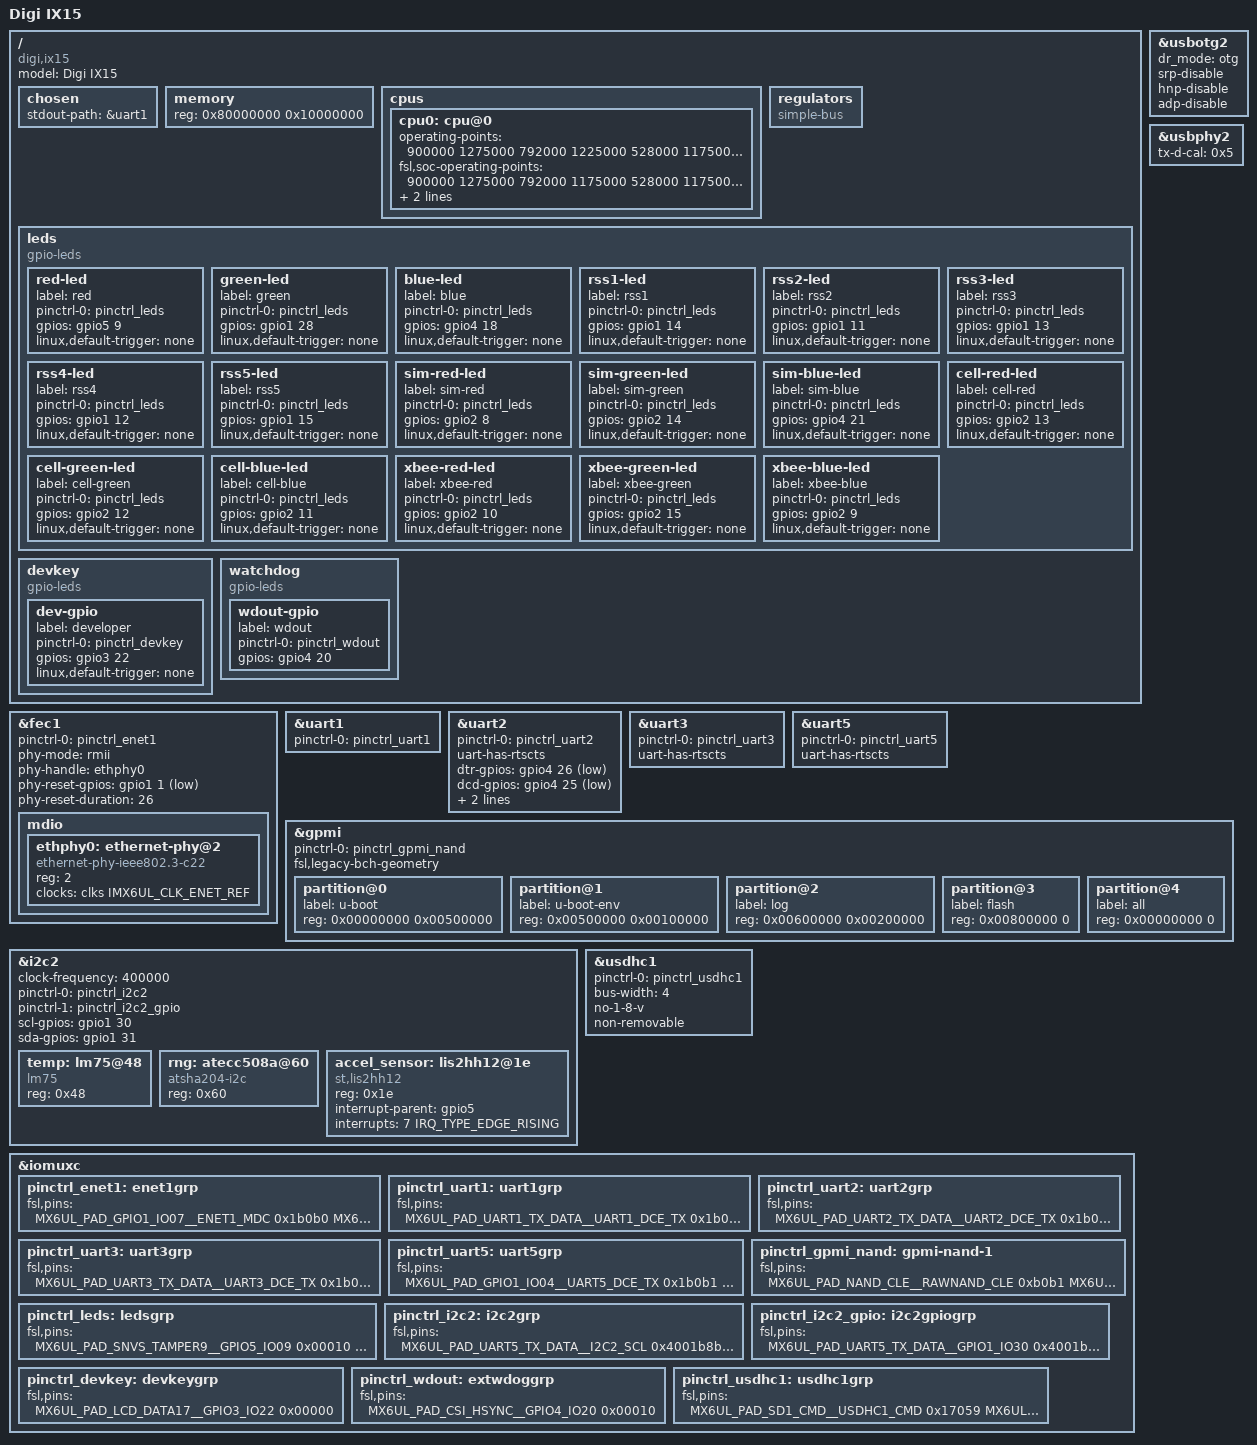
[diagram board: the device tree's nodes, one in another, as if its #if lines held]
/*
 * Copyright (C) 2016 Freescale Semiconductor, Inc.
 * Copyright (C) 2020 Digi International
 *
 * This program is free software; you can redistribute it and/or modify
 * it under the terms of the GNU General Public License version 2 as
 * published by the Free Software Foundation.
 */

/dts-v1/;

#include "imx6ull.dtsi"

/ {
	model = "Digi IX15";
	compatible = "digi,ix15", "fsl,imx6ull";

	chosen {
		stdout-path = &uart1;
	};

	memory {
		device_type = "memory";
		reg = <0x80000000 0x10000000>;
	};

	cpus {
		cpu0: cpu@0 {
			operating-points = <
                                /* kHz  uV */
                                900000  1275000
				792000	1225000
                                528000  1175000
                                396000  1025000
                                198000  950000
                        >;
                        fsl,soc-operating-points = <
                                /* KHz  uV */
                                900000  1275000
				792000	1175000
                                528000  1175000
                                396000  1175000
                                198000  1175000
                        >;
		};
	};

	regulators {
		compatible = "simple-bus";
		#address-cells = <1>;
		#size-cells = <0>;
	};

	leds {
		compatible = "gpio-leds";

		red-led {
			label = "red";
			pinctrl-names = "default";
			pinctrl-0 = <&pinctrl_leds>;
			gpios = <&gpio5 9 GPIO_ACTIVE_HIGH>;
			linux,default-trigger = "none";
		};

		green-led {
			label = "green";
			pinctrl-names = "default";
			pinctrl-0 = <&pinctrl_leds>;
			gpios = <&gpio1 28 GPIO_ACTIVE_HIGH>;
			linux,default-trigger = "none";
		};

		blue-led {
			label = "blue";
			pinctrl-names = "default";
			pinctrl-0 = <&pinctrl_leds>;
			gpios = <&gpio4 18 GPIO_ACTIVE_HIGH>;
			linux,default-trigger = "none";
		};

		rss1-led {
			label = "rss1";
			pinctrl-names = "default";
			pinctrl-0 = <&pinctrl_leds>;
			gpios = <&gpio1 14 GPIO_ACTIVE_HIGH>;
			linux,default-trigger = "none";
		};

		rss2-led {
			label = "rss2";
			pinctrl-names = "default";
			pinctrl-0 = <&pinctrl_leds>;
			gpios = <&gpio1 11 GPIO_ACTIVE_HIGH>;
			linux,default-trigger = "none";
		};

		rss3-led {
			label = "rss3";
			pinctrl-names = "default";
			pinctrl-0 = <&pinctrl_leds>;
			gpios = <&gpio1 13 GPIO_ACTIVE_HIGH>;
			linux,default-trigger = "none";
		};

		rss4-led {
			label = "rss4";
			pinctrl-names = "default";
			pinctrl-0 = <&pinctrl_leds>;
			gpios = <&gpio1 12 GPIO_ACTIVE_HIGH>;
			linux,default-trigger = "none";
		};

		rss5-led {
			label = "rss5";
			pinctrl-names = "default";
			pinctrl-0 = <&pinctrl_leds>;
			gpios = <&gpio1 15 GPIO_ACTIVE_HIGH>;
			linux,default-trigger = "none";
		};

		sim-red-led {
			label = "sim-red";
			pinctrl-names = "default";
			pinctrl-0 = <&pinctrl_leds>;
			gpios = <&gpio2 8 GPIO_ACTIVE_HIGH>;
			linux,default-trigger = "none";
		};

		sim-green-led {
			label = "sim-green";
			pinctrl-names = "default";
			pinctrl-0 = <&pinctrl_leds>;
			gpios = <&gpio2 14 GPIO_ACTIVE_HIGH>;
			linux,default-trigger = "none";
		};

		sim-blue-led {
			label = "sim-blue";
			pinctrl-names = "default";
			pinctrl-0 = <&pinctrl_leds>;
			gpios = <&gpio4 21 GPIO_ACTIVE_HIGH>;
			linux,default-trigger = "none";
		};

		cell-red-led {
			label = "cell-red";
			pinctrl-names = "default";
			pinctrl-0 = <&pinctrl_leds>;
			gpios = <&gpio2 13 GPIO_ACTIVE_HIGH>;
			linux,default-trigger = "none";
		};

		cell-green-led {
			label = "cell-green";
			pinctrl-names = "default";
			pinctrl-0 = <&pinctrl_leds>;
			gpios = <&gpio2 12 GPIO_ACTIVE_HIGH>;
			linux,default-trigger = "none";
		};

		cell-blue-led {
			label = "cell-blue";
			pinctrl-names = "default";
			pinctrl-0 = <&pinctrl_leds>;
			gpios = <&gpio2 11 GPIO_ACTIVE_HIGH>;
			linux,default-trigger = "none";
		};

		xbee-red-led {
			label = "xbee-red";
			pinctrl-names = "default";
			pinctrl-0 = <&pinctrl_leds>;
			gpios = <&gpio2 10 GPIO_ACTIVE_HIGH>;
			linux,default-trigger = "none";
		};

		xbee-green-led {
			label = "xbee-green";
			pinctrl-names = "default";
			pinctrl-0 = <&pinctrl_leds>;
			gpios = <&gpio2 15 GPIO_ACTIVE_HIGH>;
			linux,default-trigger = "none";
		};

		xbee-blue-led {
			label = "xbee-blue";
			pinctrl-names = "default";
			pinctrl-0 = <&pinctrl_leds>;
			gpios = <&gpio2 9 GPIO_ACTIVE_HIGH>;
			linux,default-trigger = "none";
		};
	};

	devkey {
		compatible = "gpio-leds";

		dev-gpio {
			label = "developer";
			pinctrl-names = "default";
			pinctrl-0 = <&pinctrl_devkey>;
			gpios = <&gpio3 22 GPIO_ACTIVE_HIGH>;
			linux,default-trigger = "none";
		};
	};

	watchdog {
		compatible = "gpio-leds";

		wdout-gpio {
			label = "wdout";
			pinctrl-names = "default";
			pinctrl-0 = <&pinctrl_wdout>;
			gpios = <&gpio4 20 GPIO_ACTIVE_HIGH>;
		};
	};
};

&cpu0 {
	arm-supply = <&reg_arm>;
	soc-supply = <&reg_soc>;
};

&fec1 {
	pinctrl-names = "default";
	pinctrl-0 = <&pinctrl_enet1>;
	phy-mode = "rmii";
	phy-handle = <&ethphy0>;
	phy-reset-gpios = <&gpio1 1 GPIO_ACTIVE_LOW>;
	phy-reset-duration = <26>;
	status = "okay";

	mdio {
		#address-cells = <1>;
		#size-cells = <0>;

		ethphy0: ethernet-phy@2 {
			compatible = "ethernet-phy-ieee802.3-c22";
			reg = <2>;
			clocks = <&clks IMX6UL_CLK_ENET_REF>;
			clock-names = "rmii-ref";
		};
	};
};

/* Console */
&uart1 {
	pinctrl-names = "default";
	pinctrl-0 = <&pinctrl_uart1>;
	status = "okay";
};

/* RS232/RS485 */
&uart2 {
	pinctrl-names = "default";
	pinctrl-0 = <&pinctrl_uart2>;
	uart-has-rtscts;
	dtr-gpios = <&gpio4 26 GPIO_ACTIVE_LOW>;
	dcd-gpios = <&gpio4 25 GPIO_ACTIVE_LOW>;
	dsr-gpios = <&gpio4 27 GPIO_ACTIVE_LOW>;
	rng-gpios = <&gpio3 3 GPIO_ACTIVE_LOW>;
	status = "okay";
};

#ifdef IX15_BLE
/* BLE */
&uart3 {
	pinctrl-names = "default";
	pinctrl-0 = <&pinctrl_uart3>;
	uart-has-rtscts;
	status = "okay";
};
#endif

/* XBee */
&uart5 {
	pinctrl-names = "default";
	pinctrl-0 = <&pinctrl_uart5>;
	uart-has-rtscts;
	status = "okay";
};

&usbotg2 {
	dr_mode = "otg";
	srp-disable;
	hnp-disable;
	adp-disable;
	status = "okay";
};

&usbphy2 {
	tx-d-cal = <0x5>;
};

&gpmi {
	pinctrl-names = "default";
	pinctrl-0 = <&pinctrl_gpmi_nand>;
	status = "okay";
	fsl,legacy-bch-geometry;

	partition@0 {
		label="u-boot";
		reg = <0x00000000 0x00500000>;
	};
	partition@1 {
		label="u-boot-env";
		reg = <0x00500000 0x00100000>;
	};
	partition@2 {
		label="log";
		reg = <0x00600000 0x00200000>;
	};
	partition@3 {
		label="flash";
		reg = <0x00800000 0>;
	};
	partition@4 {
		label="all";
		reg = <0x00000000 0>;
	};
};

&i2c2 {
	clock-frequency = <400000>;
	pinctrl-names = "default", "gpio";
	pinctrl-0 = <&pinctrl_i2c2>;
	pinctrl-1 = <&pinctrl_i2c2_gpio>;
	scl-gpios = <&gpio1 30 (GPIO_ACTIVE_HIGH | GPIO_OPEN_DRAIN)>;
	sda-gpios = <&gpio1 31 (GPIO_ACTIVE_HIGH | GPIO_OPEN_DRAIN)>;
	status = "okay";

	temp: lm75@48 {
		compatible = "lm75";
		reg = <0x48>;
	};

	rng: atecc508a@60 {
		compatible = "atsha204-i2c";
		reg = <0x60>;
	};

	accel_sensor: lis2hh12@1e {
		compatible = "st,lis2hh12";
		reg = <0x1e>;
		interrupt-parent = <&gpio5>;
		interrupts = <7 IRQ_TYPE_EDGE_RISING>;
	};
};

#ifdef IX15_EMMC
/* eMMC */
&usdhc1 {
	pinctrl-names = "default";
	pinctrl-0 = <&pinctrl_usdhc1>;
	bus-width = <4>;
	no-1-8-v;
	non-removable;
	status = "okay";
};
#endif

&iomuxc {
	pinctrl-names = "default";

	pinctrl_enet1: enet1grp {
		fsl,pins = <
			MX6UL_PAD_GPIO1_IO07__ENET1_MDC		0x1b0b0
			MX6UL_PAD_GPIO1_IO06__ENET1_MDIO	0x1b0b0
			MX6UL_PAD_ENET1_RX_EN__ENET1_RX_EN	0x1b0b0
			MX6UL_PAD_ENET1_RX_ER__ENET1_RX_ER	0x1b0b0
			MX6UL_PAD_ENET1_RX_DATA0__ENET1_RDATA00	0x1b0b0
			MX6UL_PAD_ENET1_RX_DATA1__ENET1_RDATA01	0x1b0b0
			MX6UL_PAD_ENET1_TX_EN__ENET1_TX_EN	0x1b0b0
			MX6UL_PAD_ENET1_TX_DATA0__ENET1_TDATA00	0x1b0b0
			MX6UL_PAD_ENET1_TX_DATA1__ENET1_TDATA01	0x1b0b0
			MX6UL_PAD_ENET1_TX_CLK__ENET1_REF_CLK1	0x4001b031
			/* ETHERNET POWER ENABLE */
			MX6UL_PAD_LCD_CLK__GPIO3_IO00		0x1b0b0
			/* ETHERNET RESET */
			MX6UL_PAD_GPIO1_IO01__GPIO1_IO01	0x1b0b0
		>;
	};

	/* Console */
	pinctrl_uart1: uart1grp {
		fsl,pins = <
			MX6UL_PAD_UART1_TX_DATA__UART1_DCE_TX	0x1b0b1
			MX6UL_PAD_UART1_RX_DATA__UART1_DCE_RX	0x1b0b1
		>;
	};

	/* External UART (RS232/RS485) */
	pinctrl_uart2: uart2grp {
		fsl,pins = <
			MX6UL_PAD_UART2_TX_DATA__UART2_DCE_TX	0x1b0b1
			MX6UL_PAD_UART2_RX_DATA__UART2_DCE_RX	0x1b0b1
			MX6UL_PAD_UART2_RTS_B__UART2_DCE_RTS	0x1b0b1
			MX6UL_PAD_UART2_CTS_B__UART2_DCE_CTS	0x1b0b1
			/* DTR2 */
			MX6UL_PAD_CSI_DATA04__GPIO4_IO25	0x1b0b1
			/* DCD2 */
			MX6UL_PAD_CSI_DATA05__GPIO4_IO26	0x1b0b1
			/* DSR2 */
			MX6UL_PAD_CSI_DATA06__GPIO4_IO27	0x1b0b1
			/* RNG2 */
			MX6UL_PAD_LCD_VSYNC__GPIO3_IO03		0x1b0b1
			/* RS232 ON */
			MX6UL_PAD_CSI_DATA07__GPIO4_IO28	0x1b0b1
			/* RS485 TERMINAL ENABLE */
			MX6UL_PAD_UART4_RX_DATA__GPIO1_IO29	0x1b0b1
		>;
	};

#ifdef IX15_BLE
	/* Bluetooth UART */
	pinctrl_uart3: uart3grp {
		fsl,pins = <
			MX6UL_PAD_UART3_TX_DATA__UART3_DCE_TX	0x1b0b1
			MX6UL_PAD_UART3_RX_DATA__UART3_DCE_RX	0x1b0b1
			MX6UL_PAD_UART3_RTS_B__UART3_DCE_RTS	0x1b0b1
			MX6UL_PAD_UART3_CTS_B__UART3_DCE_CTS	0x1b0b1
			/* BLE POWER ENABLE */
			MX6UL_PAD_LCD_RESET__GPIO3_IO04		0x1b0b1
			/* BLE RESET */
			MX6UL_PAD_NAND_DQS__GPIO4_IO16		0x1b0b1
			/* BLE CHIP SELECT */
			MX6UL_PAD_SNVS_TAMPER0__GPIO5_IO00	0x1b0b1
			/* BLE INTERRUPT */
			MX6UL_PAD_SNVS_TAMPER1__GPIO5_IO01	0x1b0b1
		>;
	};
#endif

	/* XBee */
	pinctrl_uart5: uart5grp {
		fsl,pins = <
			MX6UL_PAD_GPIO1_IO04__UART5_DCE_TX	0x1b0b1
			MX6UL_PAD_GPIO1_IO05__UART5_DCE_RX	0x1b0b1
			MX6UL_PAD_GPIO1_IO08__UART5_DCE_RTS	0x1b0b1
			MX6UL_PAD_GPIO1_IO09__UART5_DCE_CTS	0x1b0b1
			/* XBEE POWER ENABLE */
			MX6UL_PAD_GPIO1_IO00__GPIO1_IO00	0x1b0b1
			/* XBEE DTR */
			MX6UL_PAD_GPIO1_IO03__GPIO1_IO03	0x1b0b1
			/* XBEE RESET */
			MX6UL_PAD_GPIO1_IO02__GPIO1_IO02	0x1b0b1
		>;
	};

	pinctrl_gpmi_nand: gpmi-nand-1 {
		fsl,pins = <
			MX6UL_PAD_NAND_CLE__RAWNAND_CLE         0xb0b1
			MX6UL_PAD_NAND_ALE__RAWNAND_ALE         0xb0b1
			MX6UL_PAD_NAND_WP_B__RAWNAND_WP_B       0xb0b1
			MX6UL_PAD_NAND_READY_B__RAWNAND_READY_B 0xb000
			MX6UL_PAD_NAND_CE0_B__RAWNAND_CE0_B     0xb0b1
			MX6UL_PAD_NAND_CE1_B__RAWNAND_CE1_B     0xb0b1
			MX6UL_PAD_NAND_RE_B__RAWNAND_RE_B       0xb0b1
			MX6UL_PAD_NAND_WE_B__RAWNAND_WE_B       0xb0b1
			MX6UL_PAD_NAND_DATA00__RAWNAND_DATA00   0xb0b1
			MX6UL_PAD_NAND_DATA01__RAWNAND_DATA01   0xb0b1
			MX6UL_PAD_NAND_DATA02__RAWNAND_DATA02   0xb0b1
			MX6UL_PAD_NAND_DATA03__RAWNAND_DATA03   0xb0b1
			MX6UL_PAD_NAND_DATA04__RAWNAND_DATA04   0xb0b1
			MX6UL_PAD_NAND_DATA05__RAWNAND_DATA05   0xb0b1
			MX6UL_PAD_NAND_DATA06__RAWNAND_DATA06   0xb0b1
			MX6UL_PAD_NAND_DATA07__RAWNAND_DATA07   0xb0b1
		>;
	};

	pinctrl_leds: ledsgrp {
		fsl,pins = <
			/* RED LED */
			MX6UL_PAD_SNVS_TAMPER9__GPIO5_IO09	0x00010
			/* GREEN LED */
			MX6UL_PAD_UART4_TX_DATA__GPIO1_IO28	0x00010
			/* BLUE LED */
			MX6UL_PAD_CSI_PIXCLK__GPIO4_IO18	0x00010
			/* RSSI LED 1 */
			MX6UL_PAD_JTAG_TCK__GPIO1_IO14		0x00010
			/* RSSI LED 2 */
			MX6UL_PAD_JTAG_TMS__GPIO1_IO11		0x00010
			/* RSSI LED 3 */
			MX6UL_PAD_JTAG_TDI__GPIO1_IO13		0x00010
			/* RSSI LED 4 */
			MX6UL_PAD_JTAG_TDO__GPIO1_IO12		0x00010
			/* RSSI LED 5 */
			MX6UL_PAD_JTAG_TRST_B__GPIO1_IO15	0x00010
			/* SIM RED LED */
			MX6UL_PAD_ENET2_RX_DATA0__GPIO2_IO08	0x00010
			/* SIM GREEN LED */
			MX6UL_PAD_ENET2_TX_CLK__GPIO2_IO14	0x00010
			/* SIM BLUE LED */
			MX6UL_PAD_CSI_DATA00__GPIO4_IO21	0x00010
			/* CELL RED LED */
			MX6UL_PAD_ENET2_TX_EN__GPIO2_IO13	0x00010
			/* CELL GREEN LED */
			MX6UL_PAD_ENET2_TX_DATA1__GPIO2_IO12	0x00010
			/* CELL BLUE LED */
			MX6UL_PAD_ENET2_TX_DATA0__GPIO2_IO11	0x00010
			/* XBEE RED LED */
			MX6UL_PAD_ENET2_RX_EN__GPIO2_IO10	0x00010
			/* XBEE GREEN LED */
			MX6UL_PAD_ENET2_RX_ER__GPIO2_IO15	0x00010
			/* XBEE BLUE LED */
			MX6UL_PAD_ENET2_RX_DATA1__GPIO2_IO09	0x00010
			/* RESET DEFAULTS BUTTON */
			MX6UL_PAD_CSI_VSYNC__GPIO4_IO19		0x00000
			/* CELLULAR RESET */
			MX6UL_PAD_LCD_HSYNC__GPIO3_IO02		0x1b0b1
			/* CELLULAR POWER_ENABLE */
			MX6UL_PAD_CSI_DATA02__GPIO4_IO23	0x1b0b1
			/* SIM SELECT */
			MX6UL_PAD_CSI_DATA03__GPIO4_IO24	0x1b0b1
			/* SIM 1 DETECT */
			MX6UL_PAD_UART1_RTS_B__GPIO1_IO19	0x1b0b1
			/* SIM 2 DETECT */
			MX6UL_PAD_UART1_CTS_B__GPIO1_IO18	0x1b0b1
			/* SIM BUTTON */
			MX6UL_PAD_CSI_DATA01__GPIO4_IO22	0x00000
		>;
	};

	pinctrl_i2c2: i2c2grp {
		fsl,pins = <
			MX6UL_PAD_UART5_TX_DATA__I2C2_SCL	0x4001b8b0
			MX6UL_PAD_UART5_RX_DATA__I2C2_SDA	0x4001b8b0
		>;
	};

	pinctrl_i2c2_gpio: i2c2gpiogrp {
		fsl,pins = <
			MX6UL_PAD_UART5_TX_DATA__GPIO1_IO30	0x4001b8b0
			MX6UL_PAD_UART5_RX_DATA__GPIO1_IO31	0x4001b8b0
		>;
	};

	pinctrl_devkey: devkeygrp {
		fsl,pins = <
			MX6UL_PAD_LCD_DATA17__GPIO3_IO22	0x00000
		>;
	};

	pinctrl_wdout: extwdoggrp {
		fsl,pins = <
			MX6UL_PAD_CSI_HSYNC__GPIO4_IO20		0x00010
		>;
	};

#ifdef IX15_EMMC
	/* eMMC */
	pinctrl_usdhc1: usdhc1grp {
		fsl,pins = <
			MX6UL_PAD_SD1_CMD__USDHC1_CMD		0x17059
			MX6UL_PAD_SD1_CLK__USDHC1_CLK		0x10039
			MX6UL_PAD_SD1_DATA0__USDHC1_DATA0	0x17059
			MX6UL_PAD_SD1_DATA1__USDHC1_DATA1	0x17059
			MX6UL_PAD_SD1_DATA2__USDHC1_DATA2	0x17059
			MX6UL_PAD_SD1_DATA3__USDHC1_DATA3	0x17059
		>;
	};
#endif
};

